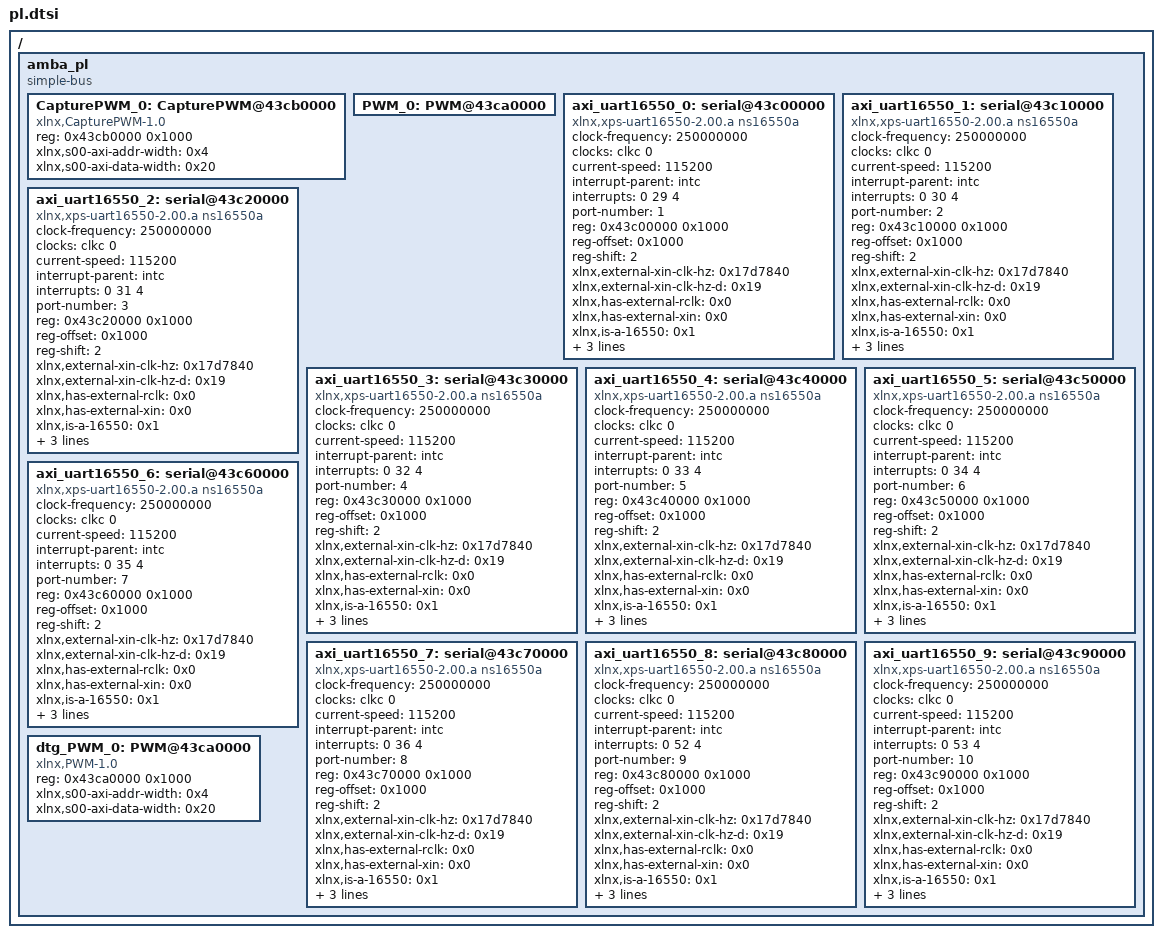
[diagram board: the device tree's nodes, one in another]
/*
 * CAUTION: This file is automatically generated by Xilinx.
 * Version:  
 * Today is: Sat Mar 31 18:34:46 2018
 */


/ {
	amba_pl: amba_pl {
		#address-cells = <1>;
		#size-cells = <1>;
		compatible = "simple-bus";
		ranges ;
		CapturePWM_0: CapturePWM@43cb0000 {
			compatible = "xlnx,CapturePWM-1.0";
			reg = <0x43cb0000 0x1000>;
			xlnx,s00-axi-addr-width = <0x4>;
			xlnx,s00-axi-data-width = <0x20>;
		};
		PWM_0: PWM@43ca0000 {
		};
		axi_uart16550_0: serial@43c00000 {
			clock-frequency = <250000000>;
			clock-names = "ref_clk";
			clocks = "clkc 0";
			compatible = "xlnx,xps-uart16550-2.00.a ns16550a";
			current-speed = <115200>;
			device_type = "serial";
			interrupt-parent = <&intc>;
			interrupts = <0 29 4>;
			port-number = <1>;
			reg = <0x43c00000 0x1000>;
			reg-offset = <0x1000>;
			reg-shift = <2>;
			xlnx,external-xin-clk-hz = <0x17d7840>;
			xlnx,external-xin-clk-hz-d = <0x19>;
			xlnx,has-external-rclk = <0x0>;
			xlnx,has-external-xin = <0x0>;
			xlnx,is-a-16550 = <0x1>;
			xlnx,s-axi-aclk-freq-hz-d = "250.0";
			xlnx,use-modem-ports = <0x1>;
			xlnx,use-user-ports = <0x1>;
		};
		axi_uart16550_1: serial@43c10000 {
			clock-frequency = <250000000>;
			clock-names = "ref_clk";
			clocks = "clkc 0";
			compatible = "xlnx,xps-uart16550-2.00.a ns16550a";
			current-speed = <115200>;
			device_type = "serial";
			interrupt-parent = <&intc>;
			interrupts = <0 30 4>;
			port-number = <2>;
			reg = <0x43c10000 0x1000>;
			reg-offset = <0x1000>;
			reg-shift = <2>;
			xlnx,external-xin-clk-hz = <0x17d7840>;
			xlnx,external-xin-clk-hz-d = <0x19>;
			xlnx,has-external-rclk = <0x0>;
			xlnx,has-external-xin = <0x0>;
			xlnx,is-a-16550 = <0x1>;
			xlnx,s-axi-aclk-freq-hz-d = "250.0";
			xlnx,use-modem-ports = <0x1>;
			xlnx,use-user-ports = <0x1>;
		};
		axi_uart16550_2: serial@43c20000 {
			clock-frequency = <250000000>;
			clock-names = "ref_clk";
			clocks = "clkc 0";
			compatible = "xlnx,xps-uart16550-2.00.a ns16550a";
			current-speed = <115200>;
			device_type = "serial";
			interrupt-parent = <&intc>;
			interrupts = <0 31 4>;
			port-number = <3>;
			reg = <0x43c20000 0x1000>;
			reg-offset = <0x1000>;
			reg-shift = <2>;
			xlnx,external-xin-clk-hz = <0x17d7840>;
			xlnx,external-xin-clk-hz-d = <0x19>;
			xlnx,has-external-rclk = <0x0>;
			xlnx,has-external-xin = <0x0>;
			xlnx,is-a-16550 = <0x1>;
			xlnx,s-axi-aclk-freq-hz-d = "250.0";
			xlnx,use-modem-ports = <0x1>;
			xlnx,use-user-ports = <0x1>;
		};
		axi_uart16550_3: serial@43c30000 {
			clock-frequency = <250000000>;
			clock-names = "ref_clk";
			clocks = "clkc 0";
			compatible = "xlnx,xps-uart16550-2.00.a ns16550a";
			current-speed = <115200>;
			device_type = "serial";
			interrupt-parent = <&intc>;
			interrupts = <0 32 4>;
			port-number = <4>;
			reg = <0x43c30000 0x1000>;
			reg-offset = <0x1000>;
			reg-shift = <2>;
			xlnx,external-xin-clk-hz = <0x17d7840>;
			xlnx,external-xin-clk-hz-d = <0x19>;
			xlnx,has-external-rclk = <0x0>;
			xlnx,has-external-xin = <0x0>;
			xlnx,is-a-16550 = <0x1>;
			xlnx,s-axi-aclk-freq-hz-d = "250.0";
			xlnx,use-modem-ports = <0x1>;
			xlnx,use-user-ports = <0x1>;
		};
		axi_uart16550_4: serial@43c40000 {
			clock-frequency = <250000000>;
			clock-names = "ref_clk";
			clocks = "clkc 0";
			compatible = "xlnx,xps-uart16550-2.00.a ns16550a";
			current-speed = <115200>;
			device_type = "serial";
			interrupt-parent = <&intc>;
			interrupts = <0 33 4>;
			port-number = <5>;
			reg = <0x43c40000 0x1000>;
			reg-offset = <0x1000>;
			reg-shift = <2>;
			xlnx,external-xin-clk-hz = <0x17d7840>;
			xlnx,external-xin-clk-hz-d = <0x19>;
			xlnx,has-external-rclk = <0x0>;
			xlnx,has-external-xin = <0x0>;
			xlnx,is-a-16550 = <0x1>;
			xlnx,s-axi-aclk-freq-hz-d = "250.0";
			xlnx,use-modem-ports = <0x1>;
			xlnx,use-user-ports = <0x1>;
		};
		axi_uart16550_5: serial@43c50000 {
			clock-frequency = <250000000>;
			clock-names = "ref_clk";
			clocks = "clkc 0";
			compatible = "xlnx,xps-uart16550-2.00.a ns16550a";
			current-speed = <115200>;
			device_type = "serial";
			interrupt-parent = <&intc>;
			interrupts = <0 34 4>;
			port-number = <6>;
			reg = <0x43c50000 0x1000>;
			reg-offset = <0x1000>;
			reg-shift = <2>;
			xlnx,external-xin-clk-hz = <0x17d7840>;
			xlnx,external-xin-clk-hz-d = <0x19>;
			xlnx,has-external-rclk = <0x0>;
			xlnx,has-external-xin = <0x0>;
			xlnx,is-a-16550 = <0x1>;
			xlnx,s-axi-aclk-freq-hz-d = "250.0";
			xlnx,use-modem-ports = <0x1>;
			xlnx,use-user-ports = <0x1>;
		};
		axi_uart16550_6: serial@43c60000 {
			clock-frequency = <250000000>;
			clock-names = "ref_clk";
			clocks = "clkc 0";
			compatible = "xlnx,xps-uart16550-2.00.a ns16550a";
			current-speed = <115200>;
			device_type = "serial";
			interrupt-parent = <&intc>;
			interrupts = <0 35 4>;
			port-number = <7>;
			reg = <0x43c60000 0x1000>;
			reg-offset = <0x1000>;
			reg-shift = <2>;
			xlnx,external-xin-clk-hz = <0x17d7840>;
			xlnx,external-xin-clk-hz-d = <0x19>;
			xlnx,has-external-rclk = <0x0>;
			xlnx,has-external-xin = <0x0>;
			xlnx,is-a-16550 = <0x1>;
			xlnx,s-axi-aclk-freq-hz-d = "250.0";
			xlnx,use-modem-ports = <0x1>;
			xlnx,use-user-ports = <0x1>;
		};
		axi_uart16550_7: serial@43c70000 {
			clock-frequency = <250000000>;
			clock-names = "ref_clk";
			clocks = "clkc 0";
			compatible = "xlnx,xps-uart16550-2.00.a ns16550a";
			current-speed = <115200>;
			device_type = "serial";
			interrupt-parent = <&intc>;
			interrupts = <0 36 4>;
			port-number = <8>;
			reg = <0x43c70000 0x1000>;
			reg-offset = <0x1000>;
			reg-shift = <2>;
			xlnx,external-xin-clk-hz = <0x17d7840>;
			xlnx,external-xin-clk-hz-d = <0x19>;
			xlnx,has-external-rclk = <0x0>;
			xlnx,has-external-xin = <0x0>;
			xlnx,is-a-16550 = <0x1>;
			xlnx,s-axi-aclk-freq-hz-d = "250.0";
			xlnx,use-modem-ports = <0x1>;
			xlnx,use-user-ports = <0x1>;
		};
		axi_uart16550_8: serial@43c80000 {
			clock-frequency = <250000000>;
			clock-names = "ref_clk";
			clocks = "clkc 0";
			compatible = "xlnx,xps-uart16550-2.00.a ns16550a";
			current-speed = <115200>;
			device_type = "serial";
			interrupt-parent = <&intc>;
			interrupts = <0 52 4>;
			port-number = <9>;
			reg = <0x43c80000 0x1000>;
			reg-offset = <0x1000>;
			reg-shift = <2>;
			xlnx,external-xin-clk-hz = <0x17d7840>;
			xlnx,external-xin-clk-hz-d = <0x19>;
			xlnx,has-external-rclk = <0x0>;
			xlnx,has-external-xin = <0x0>;
			xlnx,is-a-16550 = <0x1>;
			xlnx,s-axi-aclk-freq-hz-d = "250.0";
			xlnx,use-modem-ports = <0x1>;
			xlnx,use-user-ports = <0x1>;
		};
		axi_uart16550_9: serial@43c90000 {
			clock-frequency = <250000000>;
			clock-names = "ref_clk";
			clocks = "clkc 0";
			compatible = "xlnx,xps-uart16550-2.00.a ns16550a";
			current-speed = <115200>;
			device_type = "serial";
			interrupt-parent = <&intc>;
			interrupts = <0 53 4>;
			port-number = <10>;
			reg = <0x43c90000 0x1000>;
			reg-offset = <0x1000>;
			reg-shift = <2>;
			xlnx,external-xin-clk-hz = <0x17d7840>;
			xlnx,external-xin-clk-hz-d = <0x19>;
			xlnx,has-external-rclk = <0x0>;
			xlnx,has-external-xin = <0x0>;
			xlnx,is-a-16550 = <0x1>;
			xlnx,s-axi-aclk-freq-hz-d = "250.0";
			xlnx,use-modem-ports = <0x1>;
			xlnx,use-user-ports = <0x1>;
		};
		dtg_PWM_0: PWM@43ca0000 {
			compatible = "xlnx,PWM-1.0";
			reg = <0x43ca0000 0x1000>;
			xlnx,s00-axi-addr-width = <0x4>;
			xlnx,s00-axi-data-width = <0x20>;
		};
	};
};
